# STM32MP21_CM33 register map
File version: 0.4
CPU: CM33 r0p1, little endian, MPU, FPU, vendor SysTick, 8 interrupt priority bits
Registers are 32-bit, read-write, reset 0x0 unless marked. A register's access mark holds for its fields unless they carry their own. Offsets are from the block's base; [hi:lo] are bit positions; {n}, {i} and the like mark numbered series; 'fields as' and 'values as' point back to an identical list.

## DBGMCU — DBGMCU address block description
Base 0x440A0000
Same registers: DBGMCU_S 0x540A0000
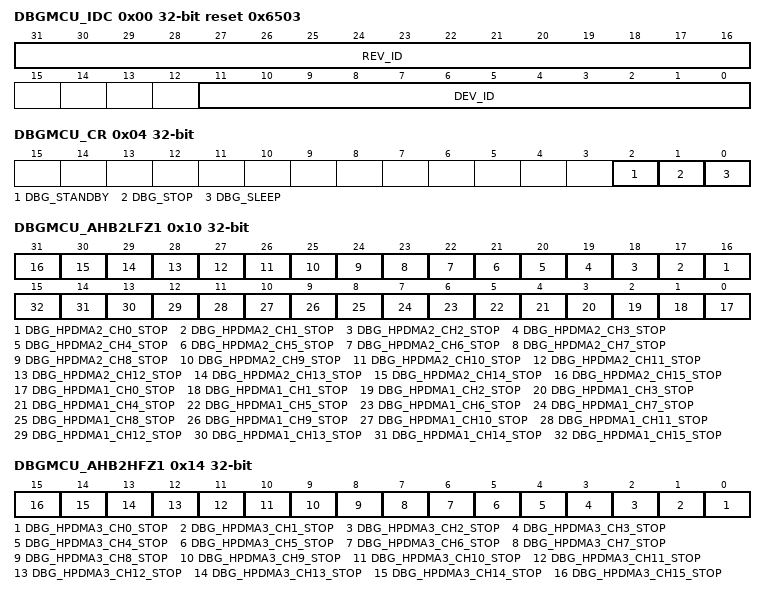
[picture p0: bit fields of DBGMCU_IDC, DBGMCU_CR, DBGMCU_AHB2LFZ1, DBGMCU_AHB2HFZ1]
0x00 DBGMCU_IDC ro reset 0x6503 (reset mask 0xFFFF) — DBGMCU identity code register
  [31:16] REV_ID — Revision
  [11:0] DEV_ID — Device identifier
    0x503=STM32MP21X
0x04 DBGMCU_CR — DBGMCU configuration register
  [2] DBG_STANDBY — Debug enable in Standby mode
    0=Normal operation; 1=Automatic clock stop/power down disabled
  [1] DBG_STOP — Debug enable in Stop mode
    0=Normal operation; 1=Automatic clock stop disabled
  [0] DBG_SLEEP — Debug enable in Sleep mode
    0=Normal operation; 1=Automatic clock stop disabled
0x08 DBGMCU_CRA35 — DBGMCU configuration register CPU1
  [1] DBG_STGEN_STOP — STGEN behavior when debug is enabled
    0=Normal operation; 1=Freeze OS timer when Cortex-A35 processor core halts in debug mode
0x10 DBGMCU_AHB2LFZ1 — DBGMCU AHB2 - lowest part - peripheral freeze register CPU1
  [all] fields
    0=Normal operation; 1=Stop in debug
  [n+16] DBG_HPDMA2_CH{n}_STOP (n=0..15) — HPDMA2_CHn suspend in debug
  [n] DBG_HPDMA1_CH{n}_STOP (n=0..15) — HPDMA1_CHn suspend in debug
0x14 DBGMCU_AHB2HFZ1 — DBGMCU AHB2 - highest part- peripheral freeze register CPU1
  [all] fields
    0=Normal operation; 1=Stop in debug
  [n] DBG_HPDMA3_CH{n}_STOP (n=0..15) — HPDMA3_CHn suspend in debug
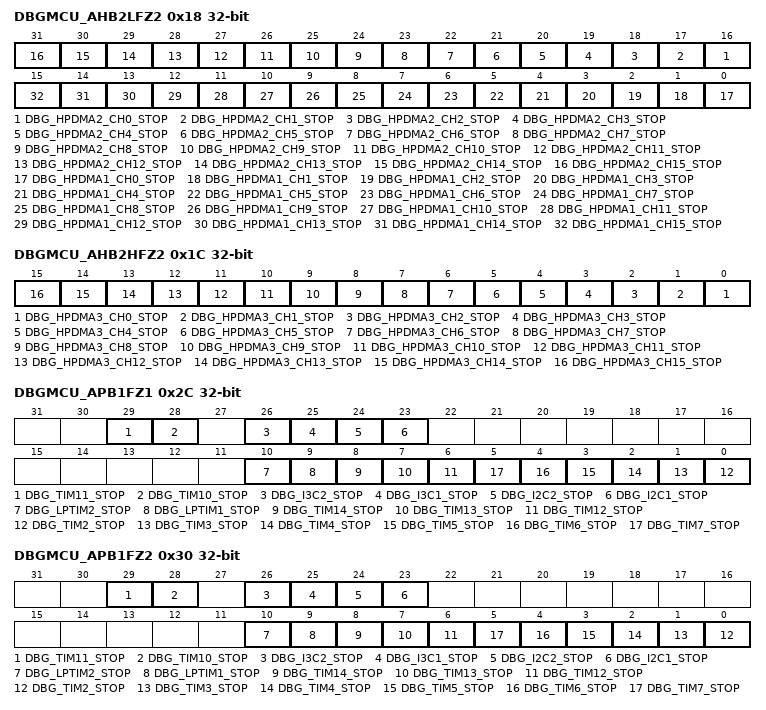
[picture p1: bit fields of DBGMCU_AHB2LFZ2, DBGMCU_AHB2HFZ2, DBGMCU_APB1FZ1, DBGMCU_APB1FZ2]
0x18 DBGMCU_AHB2LFZ2 — DBGMCU AHB2 - lowest part - peripheral freeze register CPU2
  fields as DBGMCU_AHB2LFZ1
0x1C DBGMCU_AHB2HFZ2 — DBGMCU AHB2 - highest part- peripheral freeze register CPU2
  fields as DBGMCU_AHB2HFZ1
0x2C DBGMCU_APB1FZ1 — DBGMCU APB1 peripheral freeze register CPU1
  [all] fields
    0=Normal operation; 1=Stop in debug
  [29] DBG_TIM11_STOP — TIM11 stop in debug
  [28] DBG_TIM10_STOP — TIM10 stop in debug
  [26] DBG_I3C2_STOP — I3C2 SMBUS timeout stop in debug
  [25] DBG_I3C1_STOP — I3C1 SMBUS timeout stop in debug
  [24] DBG_I2C2_STOP — I2C2 SMBUS timeout stop in debug
  [23] DBG_I2C1_STOP — I2C1 SMBUS timeout stop in debug
  [10] DBG_LPTIM2_STOP — LPTIM2 stop in debug
  [9] DBG_LPTIM1_STOP — LPTIM1 stop in debug
  [8] DBG_TIM14_STOP — TIM14 stop in debug
  [7] DBG_TIM13_STOP — TIM13 stop in debug
  [6] DBG_TIM12_STOP — TIM12 stop in debug
  [n-2] DBG_TIM{n}_STOP (n=2..7) — TIM{n} stop in debug
0x30 DBGMCU_APB1FZ2 — DBGMCU APB1 peripheral freeze register CPU2
  fields as DBGMCU_APB1FZ1
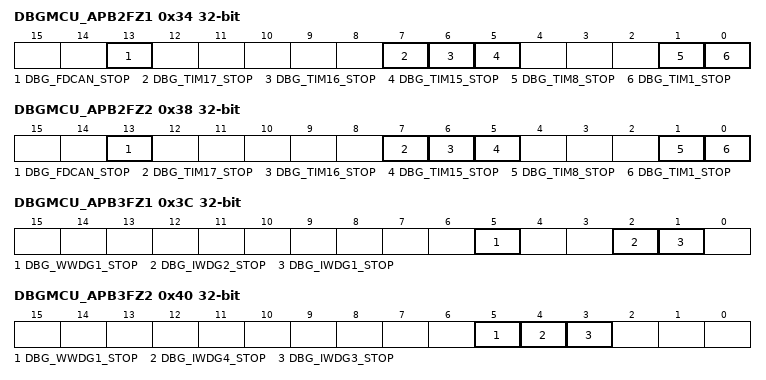
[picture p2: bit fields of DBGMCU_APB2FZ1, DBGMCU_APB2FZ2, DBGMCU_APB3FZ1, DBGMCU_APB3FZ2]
0x34 DBGMCU_APB2FZ1 — DBGMCU APB2 peripheral freeze register CPU1
  [all] fields
    0=Normal operation; 1=Stop in debug
  [13] DBG_FDCAN_STOP — FDCAN stop in debug
  [7] DBG_TIM17_STOP — TIM17 stop in debug
  [6] DBG_TIM16_STOP — TIM16 stop in debug
  [5] DBG_TIM15_STOP — TIM15 stop in debug
  [1] DBG_TIM8_STOP — TIM8 stop in debug
  [0] DBG_TIM1_STOP — TIM1 stop in debug
0x38 DBGMCU_APB2FZ2 — DBGMCU APB2 peripheral freeze register CPU2
  fields as DBGMCU_APB2FZ1
0x3C DBGMCU_APB3FZ1 — DBGMCU APB3 peripheral freeze register CPU1
  [all] fields
    0=Normal operation; 1=Stop in debug
  [5] DBG_WWDG1_STOP — WWDG1 stop in debug
  [2] DBG_IWDG2_STOP — IWDG2 stop in debug
  [1] DBG_IWDG1_STOP — IWDG1 stop in debug
0x40 DBGMCU_APB3FZ2 — DBGMCU APB3 peripheral freeze register CPU2
  [all] fields
    0=Normal operation; 1=Stop in debug
  [5] DBG_WWDG1_STOP — WWDG1 stop in debug
  [4] DBG_IWDG4_STOP — IWDG4 stop in debug
  [3] DBG_IWDG3_STOP — IWDG3 stop in debug
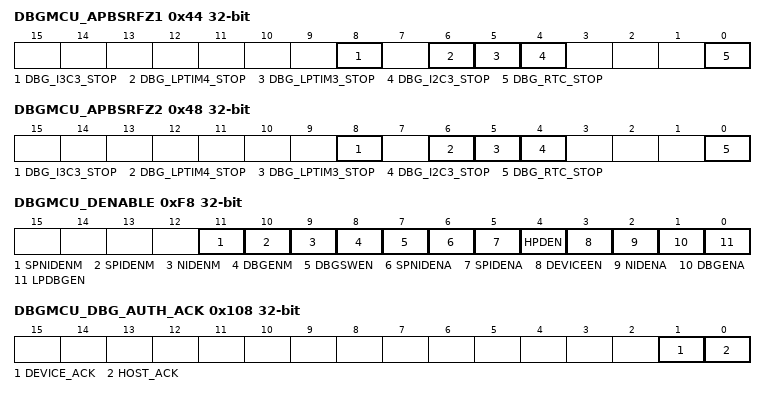
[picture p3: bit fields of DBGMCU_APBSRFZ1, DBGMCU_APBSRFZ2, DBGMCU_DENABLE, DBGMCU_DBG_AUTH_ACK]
0x44 DBGMCU_APBSRFZ1 — DBGMCU APBSR peripheral freeze register CPU1
  [all] fields
    0=Normal operation; 1=Stop in debug
  [8] DBG_I3C3_STOP — I3C3 stop in debug
  [6] DBG_LPTIM4_STOP — LPTIM4 stop in debug
  [5] DBG_LPTIM3_STOP — LPTIM3 stop in debug
  [4] DBG_I2C3_STOP — I2C3 stop in debug
  [0] DBG_RTC_STOP — RTC clock is suspended in debug
0x48 DBGMCU_APBSRFZ2 — DBGMCU APBSR peripheral freeze register CPU2
  fields as DBGMCU_APBSRFZ1
0xF8 DBGMCU_DENABLE ro — DBGMCU DENABLE value observation
  [11] SPNIDENM — secure non-invasive debug
    0=Cortex-M33 secure non-invasive debug disable; 1=Cortex-M33 secure non-invasive debug enable
  [10] SPIDENM — secure invasive debug
    0=Cortex-M33 secure invasive debug disable; 1=Cortex-M33 secure invasive debug enable
  [9] NIDENM — non-secure non-invasive debug
    0=Cortex-M33 non-secure non-invasive debug disable; 1=Cortex-M33 non-secure non-invasive debug enable
  [8] DBGENM — non-secure invasive debug
    0=Cortex-M33 non-secure invasive debug disable; 1=Cortex-M33 non-secure invasive debug enable
  [7] DBGSWEN — Invasive software debug enable
    0=Invasive software debug disable; 1=Invasive software debug enable
  [6] SPNIDENA — secure non-invasive debug
    0=Cortex-A35 secure non-invasive debug disable; 1=Cortex-A35 secure non-invasive debug enable
  [5] SPIDENA — secure invasive debug
    0=Cortex-A35 secure invasive debug disable; 1=Cortex-A35 secure invasive debug enable
  [4] HPDEN — HP debug
    0=HP debug disable; 1=HP debug enable
  [3] DEVICEEN — protection of access ports
    0=device disable; 1=device enable
  [2] NIDENA — non-secure non-invasive debug
    0=Cortex-A35 non-secure non-invasive debug disable; 1=Cortex-A35 non-secure non-invasive debug enable
  [1] DBGENA — non-secure invasive debug
    0=Cortex-A35 non-secure invasive debug disable; 1=Cortex-A35 non-secure invasive debug enable
  [0] LPDBGEN — LP debug
    0=LP debug disable; 1=LP debug enable
0x100 DBGMCU_DBG_AUTH_HOST — DBGMCU host authentication register
  [31:0] MESSAGE — Mailbox between debugger and processor
0x104 DBGMCU_DBG_AUTH_DEV — DBGMCU device authentication register
  [31:0] MESSAGE — Mailbox between debugger and processor
0x108 DBGMCU_DBG_AUTH_ACK ro — DBGMCU message read acknowledge authentication register
  [1] DEVICE_ACK — Access status to DBG_AUTH_DEV register
    1=Processor has written DBG_AUTH_DEV; 0=Debugger has read DBG_AUTH_DEV
  [0] HOST_ACK — Access status to DBG_AUTH_HOST register
    1=Debugger has written DBG_AUTH_HOST; 0=Processor has read DBG_AUTH_HOST
